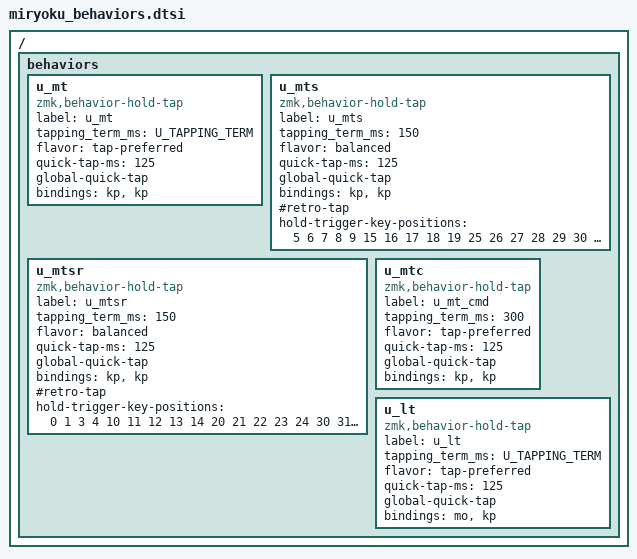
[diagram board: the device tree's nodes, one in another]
// Copyright 2022 Manna Harbour
// https://github.com/manna-harbour/miryoku

/ {
  behaviors {
    u_mt: u_mt {
      compatible = "zmk,behavior-hold-tap";
      label = "u_mt";
      #binding-cells = <2>;
      tapping_term_ms = <U_TAPPING_TERM>;
      flavor = "tap-preferred";
      quick-tap-ms = <125>;
      global-quick-tap;
      bindings = <&kp>, <&kp>;
    };
    u_mts: u_mts {
      compatible = "zmk,behavior-hold-tap";
      label = "u_mts";
      #binding-cells = <2>;
      tapping_term_ms = <150>;
      flavor = "balanced";
      quick-tap-ms = <125>;
      global-quick-tap;
      bindings = <&kp>, <&kp>;
      #retro-tap; 
      hold-trigger-key-positions = <5 6 7 8 9 15 16 17 18 19 25 26 27 28 29 30 31 32 33 34 35>;
    };
    u_mtsr: u_mtsr {
      compatible = "zmk,behavior-hold-tap";
      label = "u_mtsr";
      #binding-cells = <2>;
      tapping_term_ms = <150>;
      flavor = "balanced";
      quick-tap-ms = <125>;
      global-quick-tap;
      bindings = <&kp>, <&kp>;
      #retro-tap;
      hold-trigger-key-positions = <0 1 3 4 10 11 12 13 14 20 21 22 23 24 30 31 32 33 34 35 19>;
      //'e' (key 2 is excluded, I keep jumping to the end of lines with ctrl+e)
    };
    u_mtc: u_mtc {
      compatible = "zmk,behavior-hold-tap";
      label = "u_mt_cmd";
      #binding-cells = <2>;
      tapping_term_ms = <300>;
      flavor = "tap-preferred";
      quick-tap-ms = <125>;
      global-quick-tap;
      bindings = <&kp>, <&kp>;
    };

    u_lt: u_lt {
      compatible = "zmk,behavior-hold-tap";
      label = "u_lt";
      #binding-cells = <2>;
      tapping_term_ms = <U_TAPPING_TERM>;
      flavor = "tap-preferred";
      quick-tap-ms = <125>;
      global-quick-tap;
      bindings = <&mo>, <&kp>;
    };
  };
};
